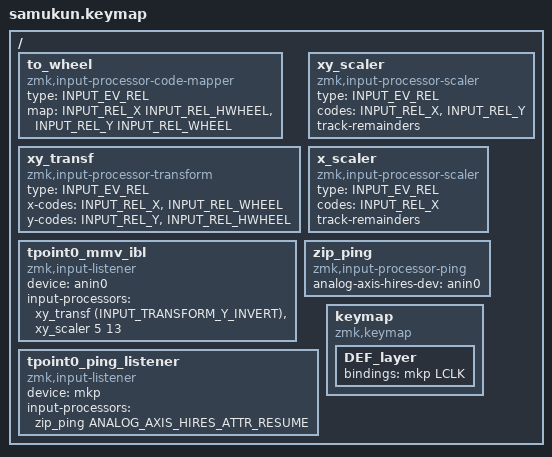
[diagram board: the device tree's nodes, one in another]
/*
 * Copyright (c) 2020 The ZMK Contributors
 *
 * SPDX-License-Identifier: MIT
 */

#include <zephyr/dt-bindings/input/input-event-codes.h>

#include <behaviors.dtsi>
#include <behaviors/mouse_keys.dtsi>
#include <behaviors/mouse_key_press.dtsi>
#include <behaviors/mouse_move.dtsi>
#include <dt-bindings/zmk/keys.h>
#include <dt-bindings/zmk/outputs.h>
#include <dt-bindings/zmk/mouse.h>
#include <dt-bindings/zmk/input_transform.h>
#include <input/processors.dtsi>

#include <zephyr/dt-bindings/input/input_analog_axis_hires.h>

#define DEF 0

/ {
        to_wheel: to_wheel {
                compatible = "zmk,input-processor-code-mapper";
                #input-processor-cells = <0>;
                type = <INPUT_EV_REL>;
                map = 
                    <INPUT_REL_X INPUT_REL_HWHEEL>,
                    <INPUT_REL_Y INPUT_REL_WHEEL>;
        };

        xy_transf: xy_transf {
                compatible = "zmk,input-processor-transform";
                #input-processor-cells = <1>;
                type = <INPUT_EV_REL>;
                x-codes = <INPUT_REL_X>, <INPUT_REL_WHEEL>;
                y-codes = <INPUT_REL_Y>, <INPUT_REL_HWHEEL>;
        };
        xy_scaler: xy_scaler {
                compatible = "zmk,input-processor-scaler";
                #input-processor-cells = <2>;
                type = <INPUT_EV_REL>;
                codes = <INPUT_REL_X>, <INPUT_REL_Y>;
                track-remainders;
        };
        x_scaler: x_scaler {
                compatible = "zmk,input-processor-scaler";
                #input-processor-cells = <2>;
                type = <INPUT_EV_REL>;
                codes = <INPUT_REL_X>;
                track-remainders;
        };
        // z_scaler: z_scaler {
        //         compatible = "zmk,input-processor-scaler";
        //         #input-processor-cells = <2>;
        //         type = <INPUT_EV_REL>;
        //         codes = <INPUT_REL_Z>;
        //         track-remainders;
        // };
        // r_transf: r_transf {
        //         compatible = "zmk,input-processor-transform";
        //         #input-processor-cells = <1>;
        //         type = <INPUT_EV_REL>;
        //         x-codes = <INPUT_REL_X>, <INPUT_REL_Y>, <INPUT_REL_Z>;
        //         y-codes = <INPUT_REL_RX>, <INPUT_REL_RY>, <INPUT_REL_RZ>;
        // };
        // tpoint0_mmv_ibl {
        //         compatible = "zmk,input-listener";
        //         device = <&spi_mlx90393>;
        //         input-processors = <&xy_transf (INPUT_TRANSFORM_XY_SWAP | INPUT_TRANSFORM_X_INVERT | INPUT_TRANSFORM_Y_INVERT)>
        //                         // ,  <&xy_scaler 1 45>, <&z_scaler 1 55>;
        //                         ,  <&xy_scaler 1 90>, <&z_scaler 1 110>;
        //                         // ,  <&xy_scaler 1 25>, <&z_scaler 1 35>
        //                         // // ,  <&r_transf (INPUT_TRANSFORM_XY_SWAP)>
        //                         // ,  <&zip_fwd_to_hid_joystick>;
        // };

        // zip_fwd_to_hid_joystick: zip_forward_fwd_to_hid_joystick {
        //         compatible = "zmk,input-processor-fwd-to-hid-joystick";
        //         #input-processor-cells = <0>;
        // };

        // jskp: hid_joystick_key_press {
        //         compatible = "zmk,behavior-hid-joystick-key-press";
        //         #binding-cells = <1>;
        // };
	// jskp_il {
	// 	compatible = "zmk,input-listener";
	// 	device = <&jskp>;
        //         input-processors = <&zip_fwd_to_hid_joystick>;
	// };

        tpoint0_mmv_ibl {
                compatible = "zmk,input-listener";
                device = <&anin0>;

                // // 4-wire strain gauge sensor board
                // input-processors = <&xy_transf (INPUT_TRANSFORM_X_INVERT)>
                //                 , <&xy_scaler 5 11>
                //                 // , <&xy_scaler 1 137> , <&to_wheel>, <&xy_transf (INPUT_TRANSFORM_Y_INVERT)>
                //                 // , <&zip_fwd_to_hid_mou2nd>
                //                 ;

                // 6-wire strain gauge sensor board
                input-processors = <&xy_transf (INPUT_TRANSFORM_Y_INVERT)>
                                , <&xy_scaler 5 13>
                                // , <&xy_scaler 1 55> , <&to_wheel>, <&xy_transf (INPUT_TRANSFORM_X_INVERT)>
                                // , <&zip_fwd_to_hid_mou2nd>
                                ;
        };
        zip_ping: zip_ping {
                compatible = "zmk,input-processor-ping";
                #input-processor-cells = <1>;
                analog-axis-hires-dev = <&anin0>;
        };
        tpoint0_ping_listener {
                compatible = "zmk,input-listener";
                device = <&mkp>;
                input-processors = <&zip_ping ANALOG_AXIS_HIRES_ATTR_RESUME>;
        };

        // zip_fwd_to_hid_mou2nd: zip_forward_fwd_to_hid_mou2nd {
        //         compatible = "zmk,input-processor-fwd-to-hid-mou2nd";
        //         #input-processor-cells = <0>;
        // };

        // mokp: hid_mou2nd_key_press {
        //         compatible = "zmk,behavior-hid-mou2nd-key-press";
        //         #binding-cells = <1>;
        // };
	// mokp_il {
	// 	compatible = "zmk,input-listener";
	// 	device = <&mokp>;
        //         input-processors = <&zip_fwd_to_hid_mou2nd>;
	// };

        // touchpad_listener {
        //         compatible = "zmk,input-listener";
        //         device = <&i2c_mxt144u>;
        // };

        // behaviors {
        //         ec_s: mouse_scroll {
        //                 compatible = "zmk,behavior-input-two-axis";
        //                 #binding-cells = <1>;
        //                 trigger-period-ms = <12>; // slow down for OTA, default is 3ms
        //                 x-input-code = <INPUT_REL_HWHEEL>;
        //                 y-input-code = <INPUT_REL_WHEEL>;
        //                 time-to-max-speed-ms = <177>;
        //                 acceleration-exponent = <0>;
        //         };
        //         rot_enc: sensor_rotate {
        //                 compatible = "zmk,behavior-sensor-rotate";
        //                 #sensor-binding-cells = <0>;
        //                 bindings = <&ec_s MOVE_Y(-37)>, <&ec_s MOVE_Y(37)>;
        //                 tap-ms = <65>;
        //         };
        // };

        keymap {
                compatible = "zmk,keymap";
                DEF_layer {
                        bindings = <

&mkp LCLK
// &jskp 0
// &mokp 0

// &kp LSHFT  &kp N2  &kp N3  &kp N4  &kp N5  &kp N6  &kp N7  &kp N8
// &kp A  &kp B  &kp C  &kp D  &kp E  &kp F  &kp G  &kp H
// &kp LS(A)  &kp LS(B)  &kp LS(C)  &kp LS(D)  &kp LS(E)  &kp LS(F)  &kp LS(G)  &kp LS(H)

// &kp N1   &kp N2   &kp N3   &kp N4
// &kp N5   &kp N6   &kp N7   &kp N8
// &kp N9   &kp N0   &kp A    &kp B
// &kp C    &kp D    &kp E    &kp F

                        >;
                        // sensor-bindings = < &rot_enc >;
                };
       };
};
